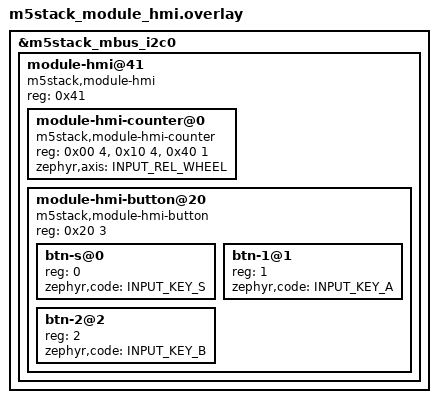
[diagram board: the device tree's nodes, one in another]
/*
 * Copyright (c) 2025 Chen Xingyu <hi@xingrz.me>
 * SPDX-License-Identifier: Apache-2.0
 */

#include <zephyr/dt-bindings/input/input-event-codes.h>

&m5stack_mbus_i2c0 {
	module-hmi@41 {
		compatible = "m5stack,module-hmi", "m5stack,mbus";
		reg = <0x41>;
		#address-cells = <1>;
		#size-cells = <1>;
		status = "okay";

		module-hmi-counter@0 {
			compatible = "m5stack,module-hmi-counter", "m5stack,expansion-rotary-input";
			reg = <0x00 4>,
			      <0x10 4>,
			      <0x40 1>;
			reg-names = "counter_val",
				    "counter_incr",
				    "counter_reset";
			status = "okay";
			zephyr,axis = <INPUT_REL_WHEEL>;
		};

		module-hmi-button@20 {
			compatible = "m5stack,module-hmi-button", "m5stack,expansion-key-input";
			reg = <0x20 3>;
			#address-cells = <1>;
			#size-cells = <0>;
			status = "okay";

			btn-s@0 {
				reg = <0>;
				zephyr,code = <INPUT_KEY_S>;
			};

			btn-1@1 {
				reg = <1>;
				zephyr,code = <INPUT_KEY_A>;
			};

			btn-2@2 {
				reg = <2>;
				zephyr,code = <INPUT_KEY_B>;
			};
		};
	};
};
